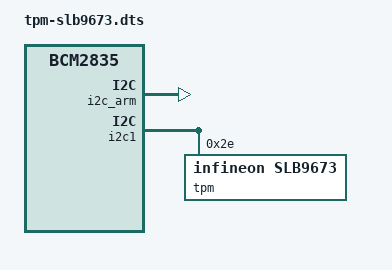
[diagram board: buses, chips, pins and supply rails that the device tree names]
/*
 * Device Tree overlay for the Infineon SLB9673 Trusted Platform Module add-on
 * boards, which can be used as a secure key storage and hwrng.
 */

/dts-v1/;
/plugin/;

/ {
        compatible = "brcm,bcm2835";

        fragment@0 {
                target = <&i2c_arm>;
                __overlay__ {
                        status = "okay";
                };
        };

        /* Add the TPM */
        fragment@1 {
                target = <&i2c1>;
                __overlay__ {
                        #address-cells = <1>;
                        #size-cells = <0>;

                        tpm@2e {
                                compatible = "infineon,slb9673", "tcg,tpm-tis-i2c";
                                reg = <0x2e>;
                                crc-checksum;
                        };
                };
        };
};
